# CTRL_MMR0_CFG0 register map
Vendor: Texas Instruments
Registers are 32-bit, read-write, reset 0x0 unless marked. A register's access mark holds for its fields unless they carry their own. Offsets are as the file gives them; [hi:lo] are bit positions; {n}, {i} and the like mark numbered series.

## CTRL_MMR0_CFG0 (part 3 of 10)
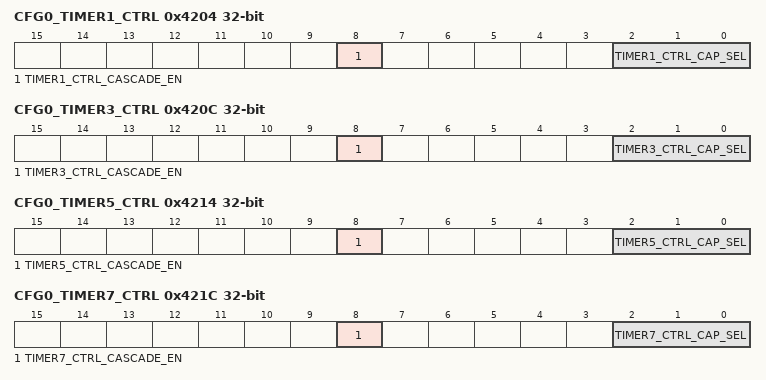
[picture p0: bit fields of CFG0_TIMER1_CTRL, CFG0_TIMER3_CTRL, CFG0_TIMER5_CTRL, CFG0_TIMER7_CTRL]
0x4204 CFG0_TIMER1_CTRL — Controls TIMER1 operation
  [8] TIMER1_CTRL_CASCADE_EN — Enables cascading of TIMER1 to TIMER0
  [2:0] TIMER1_CTRL_CAP_SEL — Selects the TIMERIO input pin for capture input signal. This control is only used when TIMER1 is configured for capture operation. Field values (Others are reserved): 3'b000 - Use TIMERIO0 pin 3'b001 - Use TIMERIO1 pin 3'b010 - Use TIMERIO2 pin 3'b011 - Use TIMERIO3 pin 3'b100 - Use TIMERIO4 pin 3'b101 - Use TIMERIO5 pin 3'b110 - Use TIMERIO6 pin 3'b111 - Use TIMERIO7 pin
0x4208 CFG0_TIMER2_CTRL — Controls TIMER2 operation
  [2:0] TIMER2_CTRL_CAP_SEL — Selects the TIMERIO input pin for capture input signal. This control is only used when TIMER2 is configured for capture operation. Field values (Others are reserved): 3'b000 - Use TIMERIO0 pin 3'b001 - Use TIMERIO1 pin 3'b010 - Use TIMERIO2 pin 3'b011 - Use TIMERIO3 pin 3'b100 - Use TIMERIO4 pin 3'b101 - Use TIMERIO5 pin 3'b110 - Use TIMERIO6 pin 3'b111 - Use TIMERIO7 pin
0x420C CFG0_TIMER3_CTRL — Controls TIMER3 operation
  [8] TIMER3_CTRL_CASCADE_EN — Enables cascading of TIMER3 to TIMER2
  [2:0] TIMER3_CTRL_CAP_SEL — Selects the TIMERIO input pin for capture input signal. This control is only used when TIMER3 is configured for capture operation. Field values (Others are reserved): 3'b000 - Use TIMERIO0 pin 3'b001 - Use TIMERIO1 pin 3'b010 - Use TIMERIO2 pin 3'b011 - Use TIMERIO3 pin 3'b100 - Use TIMERIO4 pin 3'b101 - Use TIMERIO5 pin 3'b110 - Use TIMERIO6 pin 3'b111 - Use TIMERIO7 pin
0x4210 CFG0_TIMER4_CTRL — Controls TIMER4 operation
  [2:0] TIMER4_CTRL_CAP_SEL — Selects the TIMERIO input pin for capture input signal. This control is only used when TIMER4 is configured for capture operation. Field values (Others are reserved): 3'b000 - Use TIMERIO0 pin 3'b001 - Use TIMERIO1 pin 3'b010 - Use TIMERIO2 pin 3'b011 - Use TIMERIO3 pin 3'b100 - Use TIMERIO4 pin 3'b101 - Use TIMERIO5 pin 3'b110 - Use TIMERIO6 pin 3'b111 - Use TIMERIO7 pin
0x4214 CFG0_TIMER5_CTRL — Controls TIMER5 operation
  [8] TIMER5_CTRL_CASCADE_EN — Enables cascading of TIMER5 to TIMER4
  [2:0] TIMER5_CTRL_CAP_SEL — Selects the TIMERIO input pin for capture input signal. This control is only used when TIMER5 is configured for capture operation. Field values (Others are reserved): 3'b000 - Use TIMERIO0 pin 3'b001 - Use TIMERIO1 pin 3'b010 - Use TIMERIO2 pin 3'b011 - Use TIMERIO3 pin 3'b100 - Use TIMERIO4 pin 3'b101 - Use TIMERIO5 pin 3'b110 - Use TIMERIO6 pin 3'b111 - Use TIMERIO7 pin
0x4218 CFG0_TIMER6_CTRL — Controls TIMER6 operation
  [2:0] TIMER6_CTRL_CAP_SEL — Selects the TIMERIO input pin for capture input signal. This control is only used when TIMER6 is configured for capture operation. Field values (Others are reserved): 3'b000 - Use TIMERIO0 pin 3'b001 - Use TIMERIO1 pin 3'b010 - Use TIMERIO2 pin 3'b011 - Use TIMERIO3 pin 3'b100 - Use TIMERIO4 pin 3'b101 - Use TIMERIO5 pin 3'b110 - Use TIMERIO6 pin 3'b111 - Use TIMERIO7 pin
0x421C CFG0_TIMER7_CTRL — Controls TIMER7 operation
  [8] TIMER7_CTRL_CASCADE_EN — Enables cascading of TIMER7 to TIMER6
  [2:0] TIMER7_CTRL_CAP_SEL — Selects the TIMERIO input pin for capture input signal. This control is only used when TIMER7 is configured for capture operation. Field values (Others are reserved): 3'b000 - Use TIMERIO0 pin 3'b001 - Use TIMERIO1 pin 3'b010 - Use TIMERIO2 pin 3'b011 - Use TIMERIO3 pin 3'b100 - Use TIMERIO4 pin 3'b101 - Use TIMERIO5 pin 3'b110 - Use TIMERIO6 pin 3'b111 - Use TIMERIO7 pin
0x4220 CFG0_TIMER8_CTRL — Controls TIMER8 operation
  [2:0] TIMER8_CTRL_CAP_SEL — Selects the TIMERIO input pin for capture input signal. This control is only used when TIMER8 is configured for capture operation. Field values (Others are reserved): 3'b000 - Use TIMERIO0 pin 3'b001 - Use TIMERIO1 pin 3'b010 - Use TIMERIO2 pin 3'b011 - Use TIMERIO3 pin 3'b100 - Use TIMERIO4 pin 3'b101 - Use TIMERIO5 pin 3'b110 - Use TIMERIO6 pin 3'b111 - Use TIMERIO7 pin
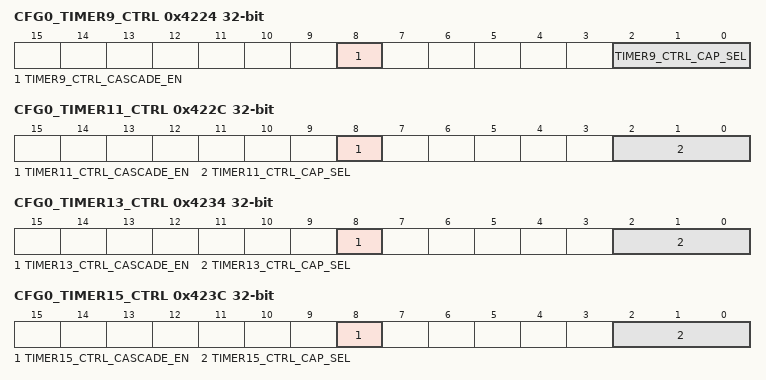
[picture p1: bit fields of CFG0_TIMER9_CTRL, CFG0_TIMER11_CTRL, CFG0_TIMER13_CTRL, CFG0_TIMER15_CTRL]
0x4224 CFG0_TIMER9_CTRL — Controls TIMER9 operation
  [8] TIMER9_CTRL_CASCADE_EN — Enables cascading of TIMER9 to TIMER8
  [2:0] TIMER9_CTRL_CAP_SEL — Selects the TIMERIO input pin for capture input signal. This control is only used when TIMER9 is configured for capture operation. Field values (Others are reserved): 3'b000 - Use TIMERIO0 pin 3'b001 - Use TIMERIO1 pin 3'b010 - Use TIMERIO2 pin 3'b011 - Use TIMERIO3 pin 3'b100 - Use TIMERIO4 pin 3'b101 - Use TIMERIO5 pin 3'b110 - Use TIMERIO6 pin 3'b111 - Use TIMERIO7 pin
0x4228 CFG0_TIMER10_CTRL — Controls TIMER10 operation
  [2:0] TIMER10_CTRL_CAP_SEL — Selects the TIMERIO input pin for capture input signal. This control is only used when TIMER10 is configured for capture operation. Field values (Others are reserved): 3'b000 - Use TIMERIO0 pin 3'b001 - Use TIMERIO1 pin 3'b010 - Use TIMERIO2 pin 3'b011 - Use TIMERIO3 pin 3'b100 - Use TIMERIO4 pin 3'b101 - Use TIMERIO5 pin 3'b110 - Use TIMERIO6 pin 3'b111 - Use TIMERIO7 pin
0x422C CFG0_TIMER11_CTRL — Controls TIMER11 operation
  [8] TIMER11_CTRL_CASCADE_EN — Enables cascading of TIMER11 to TIMER10
  [2:0] TIMER11_CTRL_CAP_SEL — Selects the TIMERIO input pin for capture input signal. This control is only used when TIMER11 is configured for capture operation. Field values (Others are reserved): 3'b000 - Use TIMERIO0 pin 3'b001 - Use TIMERIO1 pin 3'b010 - Use TIMERIO2 pin 3'b011 - Use TIMERIO3 pin 3'b100 - Use TIMERIO4 pin 3'b101 - Use TIMERIO5 pin 3'b110 - Use TIMERIO6 pin 3'b111 - Use TIMERIO7 pin
0x4230 CFG0_TIMER12_CTRL — Controls TIMER12 operation
  [2:0] TIMER12_CTRL_CAP_SEL — Selects the TIMERIO input pin for capture input signal. This control is only used when TIMER12 is configured for capture operation. Field values (Others are reserved): 3'b000 - Use TIMERIO0 pin 3'b001 - Use TIMERIO1 pin 3'b010 - Use TIMERIO2 pin 3'b011 - Use TIMERIO3 pin 3'b100 - Use TIMERIO4 pin 3'b101 - Use TIMERIO5 pin 3'b110 - Use TIMERIO6 pin 3'b111 - Use TIMERIO7 pin
0x4234 CFG0_TIMER13_CTRL — Controls TIMER13 operation
  [8] TIMER13_CTRL_CASCADE_EN — Enables cascading of TIMER13 to TIMER12
  [2:0] TIMER13_CTRL_CAP_SEL — Selects the TIMERIO input pin for capture input signal. This control is only used when TIMER13 is configured for capture operation. Field values (Others are reserved): 3'b000 - Use TIMERIO0 pin 3'b001 - Use TIMERIO1 pin 3'b010 - Use TIMERIO2 pin 3'b011 - Use TIMERIO3 pin 3'b100 - Use TIMERIO4 pin 3'b101 - Use TIMERIO5 pin 3'b110 - Use TIMERIO6 pin 3'b111 - Use TIMERIO7 pin
0x4238 CFG0_TIMER14_CTRL — Controls TIMER14 operation
  [2:0] TIMER14_CTRL_CAP_SEL — Selects the TIMERIO input pin for capture input signal. This control is only used when TIMER14 is configured for capture operation. Field values (Others are reserved): 3'b000 - Use TIMERIO0 pin 3'b001 - Use TIMERIO1 pin 3'b010 - Use TIMERIO2 pin 3'b011 - Use TIMERIO3 pin 3'b100 - Use TIMERIO4 pin 3'b101 - Use TIMERIO5 pin 3'b110 - Use TIMERIO6 pin 3'b111 - Use TIMERIO7 pin
0x423C CFG0_TIMER15_CTRL — Controls TIMER15 operation
  [8] TIMER15_CTRL_CASCADE_EN — Enables cascading of TIMER15 to TIMER14
  [2:0] TIMER15_CTRL_CAP_SEL — Selects the TIMERIO input pin for capture input signal. This control is only used when TIMER15 is configured for capture operation. Field values (Others are reserved): 3'b000 - Use TIMERIO0 pin 3'b001 - Use TIMERIO1 pin 3'b010 - Use TIMERIO2 pin 3'b011 - Use TIMERIO3 pin 3'b100 - Use TIMERIO4 pin 3'b101 - Use TIMERIO5 pin 3'b110 - Use TIMERIO6 pin 3'b111 - Use TIMERIO7 pin
0x4240 CFG0_TIMER16_CTRL — Controls TIMER16 operation
  [2:0] TIMER16_CTRL_CAP_SEL — Selects the TIMERIO input pin for capture input signal. This control is only used when TIMER16 is configured for capture operation. Field values (Others are reserved): 3'b000 - Use TIMERIO0 pin 3'b001 - Use TIMERIO1 pin 3'b010 - Use TIMERIO2 pin 3'b011 - Use TIMERIO3 pin 3'b100 - Use TIMERIO4 pin 3'b101 - Use TIMERIO5 pin 3'b110 - Use TIMERIO6 pin 3'b111 - Use TIMERIO7 pin
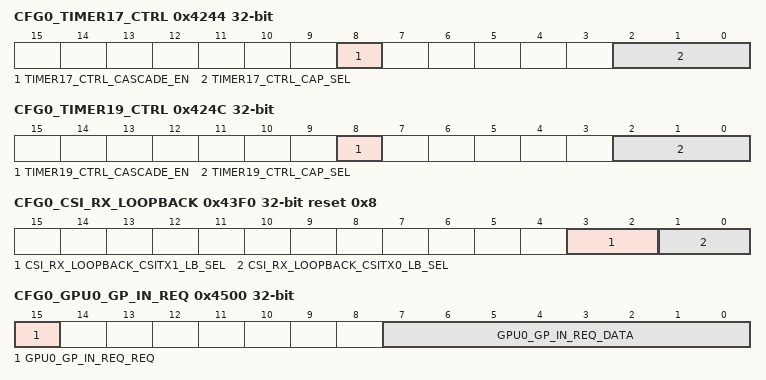
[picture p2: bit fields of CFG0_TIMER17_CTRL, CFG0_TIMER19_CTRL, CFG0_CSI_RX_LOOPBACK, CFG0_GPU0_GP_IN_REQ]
0x4244 CFG0_TIMER17_CTRL — Controls TIMER17 operation
  [8] TIMER17_CTRL_CASCADE_EN — Enables cascading of TIMER17 to TIMER16
  [2:0] TIMER17_CTRL_CAP_SEL — Selects the TIMERIO input pin for capture input signal. This control is only used when TIMER17 is configured for capture operation. Field values (Others are reserved): 3'b000 - Use TIMERIO0 pin 3'b001 - Use TIMERIO1 pin 3'b010 - Use TIMERIO2 pin 3'b011 - Use TIMERIO3 pin 3'b100 - Use TIMERIO4 pin 3'b101 - Use TIMERIO5 pin 3'b110 - Use TIMERIO6 pin 3'b111 - Use TIMERIO7 pin
0x4248 CFG0_TIMER18_CTRL — Controls TIMER18 operation
  [2:0] TIMER18_CTRL_CAP_SEL — Selects the TIMERIO input pin for capture input signal. This control is only used when TIMER18 is configured for capture operation. Field values (Others are reserved): 3'b000 - Use TIMERIO0 pin 3'b001 - Use TIMERIO1 pin 3'b010 - Use TIMERIO2 pin 3'b011 - Use TIMERIO3 pin 3'b100 - Use TIMERIO4 pin 3'b101 - Use TIMERIO5 pin 3'b110 - Use TIMERIO6 pin 3'b111 - Use TIMERIO7 pin
0x424C CFG0_TIMER19_CTRL — Controls TIMER19 operation
  [8] TIMER19_CTRL_CASCADE_EN — Enables cascading of TIMER19 to TIMER18
  [2:0] TIMER19_CTRL_CAP_SEL — Selects the TIMERIO input pin for capture input signal. This control is only used when TIMER19 is configured for capture operation. Field values (Others are reserved): 3'b000 - Use TIMERIO0 pin 3'b001 - Use TIMERIO1 pin 3'b010 - Use TIMERIO2 pin 3'b011 - Use TIMERIO3 pin 3'b100 - Use TIMERIO4 pin 3'b101 - Use TIMERIO5 pin 3'b110 - Use TIMERIO6 pin 3'b111 - Use TIMERIO7 pin
{0x4280+4i} CFG0_TIMERIO{i}_CTRL (i=0..7) — Controls Timer IO muxing
  [4:0] TIMERIO{i}_CTRL_OUT_SEL — Selects the source of the TIMERIO{i} output Field values (Others are reserved): 5'b00000 - TIMERIO{i} is driven by TIMER0 output 5'b00001 - TIMERIO{i} is driven by TIMER1 output 5'b00010 - TIMERIO{i} is driven by TIMER2 output 5'b00011 - TIMERIO{i} is driven by TIMER3 output 5'b00100 - TIMERIO{i} is driven by TIMER4 output 5'b00101 - TIMERIO{i} is driven by TIMER5 output 5'b00110 - TIMERIO{i} is driven by TIMER6 output 5'b00111 - TIMERIO{i} is driven by TIMER7 output 5'b01000 - TIMERIO{i} is driven by TIMER8 output 5'b01001 - TIMERIO{i} is driven by TIMER9 output 5'b01010 - TIMERIO{i} is driven by TIMER10 output 5'b01011 - TIMERIO{i} is driven by TIMER11 output 5'b01100 - TIMERIO{i} is driven by TIMER12 output 5'b01101 - TIMERIO{i} is driven by TIMER13 output 5'b01110 - TIMERIO{i} is driven by TIMER14 output 5'b01111 - TIMERIO{i} is driven by TIMER15 output 5'b10000 - TIMERIO{i} is driven by TIMER16 output 5'b10001 - TIMERIO{i} is driven by TIMER17 output 5'b10010 - TIMERIO{i} is driven by TIMER18 output 5'b10011 - TIMERIO{i} is driven by TIMER19 output
0x42E0 CFG0_I2C0_CTRL — Controls I2C0 operation for open drain I/Os
  [0] I2C0_CTRL_HS_MCS_EN — HS Mode master current source enable.When set, enables the current-source pull-up on the SCL output. Only one master on the I2C bus should enable SCL current sourcing.
0x4300 CFG0_DPHY_TX0_CTRL — Controls DPHY_TX0 operation
  [1:0] DPHY_TX0_CTRL_LANE_FUNC_SEL — Selects the source for the 4 lanes of DPHY_TX 0 Field values (Others are reserved): 2'b00 - IP1 (DSI_0 PPI0) 2'b01 - IP2 (CSI-TX0)
0x4304 CFG0_DPHY_TX1_CTRL — Controls DPHY_TX1 operation
  [1:0] DPHY_TX1_CTRL_LANE_FUNC_SEL — Selects the source for the 4 lanes of DPHY_TX 1 Field values (Others are reserved): 2'b00 - IP1 (DSI_1 PPI0) 2'b01 - IP2 (CSI-TX1)
0x4310 CFG0_EDP0_CTRL — Controls eDP0 operation
  [8] EDP0_CTRL_RESET_ISO — Reset isolationWhen set, enables reset isolation of eDP PHY
0x4320 CFG0_VPAC0_CAL0_CTRL — Controls VPAC0 Camera Adaptive Layer 0 interface operation
  [1:0] VPAC0_CAL0_CTRL_CAL_SEL — Selects the CSI_RX source for the VPAC CAL0 input Field values (Others are reserved): 2'b00 - CSI-RX 0 2'b01 - CSI-RX 1 2'b10 - CSI-RX 2 2'b11 - Reserved
0x4330 CFG0_VPAC1_CAL0_CTRL — Controls VPAC1 Camera Adaptive Layer 0 interface operation
  [1:0] VPAC1_CAL0_CTRL_CAL_SEL — Selects the CSI_RX source for the VPAC CAL0 input Field values (Others are reserved): 2'b00 - CSI-RX 0 2'b01 - CSI-RX 1 2'b10 - CSI-RX 2 2'b11 - Reserved
0x43F0 CFG0_CSI_RX_LOOPBACK reset 0x8 — Controls loopback of CSI-RX inputs to CSI-TX inputs for diagnostics.
  [3:2] CSI_RX_LOOPBACK_CSITX1_LB_SEL — Selects the CSI-RX loopback source for CSI-TX1 Field values (Others are reserved): 2'b00 - CSI-RX 0 2'b01 - CSI-RX 1 2'b10 - CSI-RX 2 2'b11 - Reserved
  [1:0] CSI_RX_LOOPBACK_CSITX0_LB_SEL — Selects the CSI-RX loopback source for CSI-TX0. Field values (Others are reserved): 2'b00 - CSI-RX 0 2'b01 - CSI-RX 1 2'b10 - CSI-RX 2 2'b11 - Reserved
0x4500 CFG0_GPU0_GP_IN_REQ — Generates GPIO input event to GPU0
  [15] GPU0_GP_IN_REQ_REQ — Input request. This bit is set to generate a GPIO request to the GPU to read the requestor data input. This bit should be cleared by the requestor after the GPU has acknowledged the request.
  [7:0] GPU0_GP_IN_REQ_DATA — GPIO requestor data input to the GPU
0x4504 CFG0_GPU0_GP_IN_ACK ro — Acknowledge for GPIO input event from GPU0
  [15] GPU0_GP_IN_ACK_ACK — Input acknowledge. The GPU will set this bit to acknowledge a GPIO input request. This will generate a gpu_gpio_ack interrupt which will be cleared when the requestor clears the req bit in the GPU_GP_IN_REQ register.
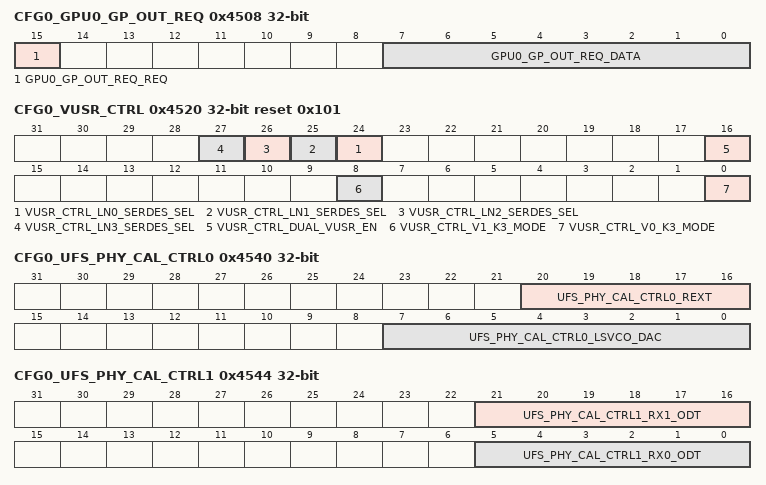
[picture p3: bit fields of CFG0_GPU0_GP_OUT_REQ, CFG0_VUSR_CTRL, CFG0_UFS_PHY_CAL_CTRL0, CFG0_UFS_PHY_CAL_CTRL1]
0x4508 CFG0_GPU0_GP_OUT_REQ ro — Generates GPIO output event from GPU0
  [15] GPU0_GP_OUT_REQ_REQ — Output request. This bit is set to generate a GPIO request from the GPU to read the requestor data output. This will generate a gpu_gpio_req interrupt which will be cleared when the receiver clears the ack bit in the GPU_GPIO_OUT_ACK register. This bit will be cleared by the GPU after the request has been acknowledged.
  [7:0] GPU0_GP_OUT_REQ_DATA — GPIO requestor data output from the GPU
0x450C CFG0_GPU0_GP_OUT_ACK — Acknowledge for GPIO output event to GPU0
  [15] GPU0_GP_OUT_ACK_ACK — Output acknowledge. The receiver of the gpu_gpio_req interrupt will set this bit to acknowledge the GPIO output request. This bit is cleared when the GPU deasserts its gpio_output_req signal.
0x4520 CFG0_VUSR_CTRL reset 0x101 — Controls operation of the dual VUSR (Hyperlink) module
  [n+24] VUSR_CTRL_LN{n}_SERDES_SEL (n=0..3) — Serdes Selection - Lane {n}The Hyperlink lane{n} interface can be mapped to 2 different SERDES lanes. This bit selects which SERDES drives the VUSR lane{n} PIPE interface input clock, data and control signals. Programming should align with the SERDES0_LN{n}_CTRL and SERDES4_LN{n}_CTRL lane_func_sel programming. 0 - SERDES0 Ln{n} drives VUSR lane{n} inputs 1 - SERDES4 Ln{n} drives VUSR lane{n} inputs
  [16] VUSR_CTRL_DUAL_VUSR_EN — Selects single or dual VUSR interface operation 0 - Single VUSR interface (VUSR0) enabled 1 - Dual VUSR interface (VUSR0 & VUSR1) enabled
  [8] VUSR_CTRL_V1_K3_MODE — VUSR1 interface operational mode 0 - Legacy (KS2) addressing/interface mode 1 - Enhanced (KS3) addressing/interface mode
  [0] VUSR_CTRL_V0_K3_MODE — VUSR0 interface operational mode 0 - Legacy (KS2) addressing/interface mode 1 - Enhanced (KS3) addressing/interface mode
0x4540 CFG0_UFS_PHY_CAL_CTRL0 — Controls UFS LSVCO calibration
  [20:16] UFS_PHY_CAL_CTRL0_REXT — REXT calibration trim value
  [7:0] UFS_PHY_CAL_CTRL0_LSVCO_DAC — LS VCO calibration trim value
0x4544 CFG0_UFS_PHY_CAL_CTRL1 — Controls UFS RX calibration
  [21:16] UFS_PHY_CAL_CTRL1_RX1_ODT — RX1 DP/DN 100-ohm differential impedance trim value
  [5:0] UFS_PHY_CAL_CTRL1_RX0_ODT — RX0 DP/DN 100-ohm differential impedance trim value
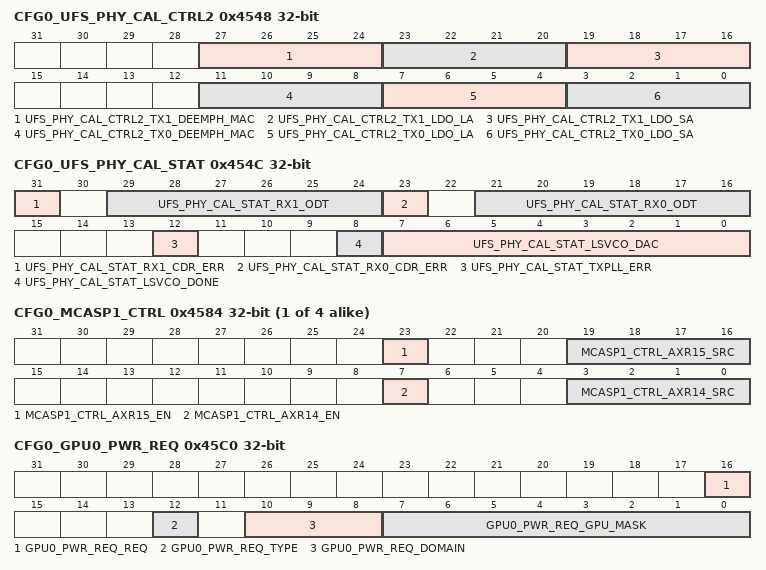
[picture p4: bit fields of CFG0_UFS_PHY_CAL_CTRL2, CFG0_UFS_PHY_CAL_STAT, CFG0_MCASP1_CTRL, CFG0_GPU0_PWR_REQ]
0x4548 CFG0_UFS_PHY_CAL_CTRL2 — Controls UFS TX calibration
  [27:24] UFS_PHY_CAL_CTRL2_TX1_DEEMPH_MAC — TX1 DP/DN de-emphasis trim value
  [23:20] UFS_PHY_CAL_CTRL2_TX1_LDO_LA — TX1 DP/DN large amplitude trim value
  [19:16] UFS_PHY_CAL_CTRL2_TX1_LDO_SA — TX1 DP/DN small amplitude trim value
  [11:8] UFS_PHY_CAL_CTRL2_TX0_DEEMPH_MAC — TX0 DP/DN de-emphasis trim value
  [7:4] UFS_PHY_CAL_CTRL2_TX0_LDO_LA — TX0 DP/DN large amplitude trim value
  [3:0] UFS_PHY_CAL_CTRL2_TX0_LDO_SA — TX0 DP/DN small amplitude trim value
0x454C CFG0_UFS_PHY_CAL_STAT ro — Shows UFS calibration procedure results
  [31] UFS_PHY_CAL_STAT_RX1_CDR_ERR — RX1 CDR calibration timeout error
  [29:24] UFS_PHY_CAL_STAT_RX1_ODT — RX1 DP/DN ODT calibration result
  [23] UFS_PHY_CAL_STAT_RX0_CDR_ERR — RX0 CDR calibration timeout error
  [21:16] UFS_PHY_CAL_STAT_RX0_ODT — RX0 DP/DN ODT calibration result
  [12] UFS_PHY_CAL_STAT_TXPLL_ERR — TX calibration timeout error
  [8] UFS_PHY_CAL_STAT_LSVCO_DONE — LS VCO calibration trim done
  [7:0] UFS_PHY_CAL_STAT_LSVCO_DAC — LS VCO calibration trim result
{0x4580+4i} CFG0_MCASP{i}_CTRL (i=1..4) — Controls McASP{i} operation
  [23] MCASP{i}_CTRL_AXR15_EN — Enable AXR15 receive data. 0 - AXR15 input driven 1'b0 1 - AXR15 input driven by AFSR/X input selected by axr15_src value
  [19:16] MCASP{i}_CTRL_AXR15_SRC — Selects one of the AFSX or AFSR inputs as the AXR15 data input Field values (Others are reserved): 4'b0000 - McASP0_AFSR 4'b0001 - McASP0_AFSX 4'b0010 - McASP1_AFSR 4'b0011 - McASP1_AFSX 4'b0100 - McASP2_AFSR 4'b0101 - McASP2_AFSX 4'b0110 - McASP3_AFSR 4'b0111 - McASP3_AFSX 4'b1000 - McASP4_AFSR 4'b1001 - McASP4_AFSX 4'b1010 - 0 4'b1011 - 0 4'b1100 - 0 4'b1101 - 0 4'b1110 - 0 4'b1111 - 0
  [7] MCASP{i}_CTRL_AXR14_EN — Enable AXR14 receive data. 0 - AXR14 input driven 1'b0 1 - AXR14 input driven by AFSR/X input selected by axr14_src value
  [3:0] MCASP{i}_CTRL_AXR14_SRC — Selects one of the AFSX or AFSR inputs as the AXR14 data input Field values (Others are reserved): 4'b0000 - McASP0_AFSR 4'b0001 - McASP0_AFSX 4'b0010 - McASP1_AFSR 4'b0011 - McASP1_AFSX 4'b0100 - McASP2_AFSR 4'b0101 - McASP2_AFSX 4'b0110 - McASP3_AFSR 4'b0111 - McASP3_AFSX 4'b1000 - McASP4_AFSR 4'b1001 - McASP4_AFSX 4'b1010 - 0 4'b1011 - 0 4'b1100 - 0 4'b1101 - 0 4'b1110 - 0 4'b1111 - 0
0x45C0 CFG0_GPU0_PWR_REQ ro — Indicates GPU0 power control interface requests
  [16] GPU0_PWR_REQ_REQ — Power control request. This bit is set by the GPU to request a Power Management event to the PM processor. This will generate a gpu0_pwr_req interrupt. The interrupt is cleared only when the GPU clears its pwrctrl_gpu_req output.
  [12] GPU0_PWR_REQ_TYPE — GPU request type. 0 - Power Down request 1 - Power Up request
  [10:8] GPU0_PWR_REQ_DOMAIN — GPU request mask. Indicates GPU domain to which the power event applies. For mapping refer to GPU RGX_CR_POWER_EVENT register.
  [7:0] GPU0_PWR_REQ_GPU_MASK — GPU request mask. One bit per GPU indicating to which GPUs the power event applies. Mask bits are indexed by GPU_ID
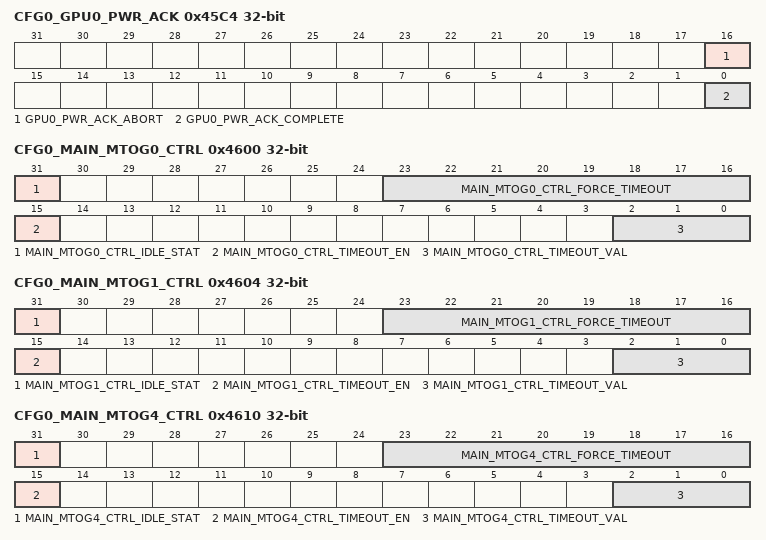
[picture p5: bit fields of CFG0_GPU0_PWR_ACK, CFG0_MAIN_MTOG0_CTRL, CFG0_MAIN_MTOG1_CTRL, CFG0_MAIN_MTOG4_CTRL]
0x45C4 CFG0_GPU0_PWR_ACK — Controls GPU0 power control interface request acknowledgement
  [16] GPU0_PWR_ACK_ABORT — Power control abort. This bit is set by the PM processor to that the GPU power control request could not be completed. The bit is cleared to 0 when gpu0_pwr_req goes low.
  [0] GPU0_PWR_ACK_COMPLETE — Power control complete. This bit is set by the PM processor to indicate sucessful completion of the GPU power control request. The bit is cleared to 0 when gpu0_pwr_req goes low.
0x4600 CFG0_MAIN_MTOG0_CTRL access per field — Controls timeout operation of read transactions from the GIC master port
  [31] MAIN_MTOG0_CTRL_IDLE_STAT ro — Idle statusWhen high, indicates MTOG0 is idle.
  [23:16] MAIN_MTOG0_CTRL_FORCE_TIMEOUT rw — Force TimeoutForces a flush of the interface transactions. This bitfield is only relevant if timeout_en=1. After forcing a timeout by writing the encoded value, the force_timeout and timeout_en bitfields must be cleared to clear the timeout before re-enabling the gasket. 8'h95 - Force a gasket timeoutAll others - Normal operation
  [15] MAIN_MTOG0_CTRL_TIMEOUT_EN rw — Timeout Enable 1'b0 - Disable the gasket. Clear the interrupt and reset the counter 1'b1 - Enable the timeout gasket functions
  [2:0] MAIN_MTOG0_CTRL_TIMEOUT_VAL rw — Gasket Timeout ValueSelects the number of clock cycles before the interface is considered to have timed out Field values (Others are reserved): 3'b000 - 1024 clock cycles 3'b001 - 4096 clock cycles 3'b010 - 16,384 clock cycles 3'b011 - 65,536 clock cycles 3'b100 - 262,144 clock cycles 3'b101 - 1,048,576 clock cycles 3'b110 - 2,097,152 clock cycles 3'b111 - 4,194,303 clock cycles
0x4604 CFG0_MAIN_MTOG1_CTRL access per field — Controls timeout operation of write transactions from the GIC master port
  [31] MAIN_MTOG1_CTRL_IDLE_STAT ro — Idle statusWhen high, indicates MTOG1 is idle.
  [23:16] MAIN_MTOG1_CTRL_FORCE_TIMEOUT rw — Force TimeoutForces a flush of the interface transactions. This bitfield is only relevant if timeout_en=1. After forcing a timeout by writing the encoded value, the force_timeout and timeout_en bitfields must be cleared to clear the timeout before re-enabling the gasket. 8'h95 - Force a gasket timeoutAll others - Normal operation
  [15] MAIN_MTOG1_CTRL_TIMEOUT_EN rw — Timeout Enable 1'b0 - Disable the gasket. Clear the interrupt and reset the counter 1'b1 - Enable the timeout gasket functions
  [2:0] MAIN_MTOG1_CTRL_TIMEOUT_VAL rw — Gasket Timeout ValueSelects the number of clock cycles before the interface is considered to have timed out Field values (Others are reserved): 3'b000 - 1024 clock cycles 3'b001 - 4096 clock cycles 3'b010 - 16,384 clock cycles 3'b011 - 65,536 clock cycles 3'b100 - 262,144 clock cycles 3'b101 - 1,048,576 clock cycles 3'b110 - 2,097,152 clock cycles 3'b111 - 4,194,303 clock cycles
0x4610 CFG0_MAIN_MTOG4_CTRL access per field — Controls timeout operation of read transactions from the eMMC1 master port
  [31] MAIN_MTOG4_CTRL_IDLE_STAT ro — Idle statusWhen high, indicates MTOG4 is idle.
  [23:16] MAIN_MTOG4_CTRL_FORCE_TIMEOUT rw — Force TimeoutForces a flush of the interface transactions. This bitfield is only relevant if timeout_en=1. After forcing a timeout by writing the encoded value, the force_timeout and timeout_en bitfields must be cleared to clear the timeout before re-enabling the gasket. 8'h95 - Force a gasket timeoutAll others - Normal operation
  [15] MAIN_MTOG4_CTRL_TIMEOUT_EN rw — Timeout Enable 1'b0 - Disable the gasket. Clear the interrupt and reset the counter 1'b1 - Enable the timeout gasket functions
  [2:0] MAIN_MTOG4_CTRL_TIMEOUT_VAL rw — Gasket Timeout ValueSelects the number of clock cycles before the interface is considered to have timed out Field values (Others are reserved): 3'b000 - 1024 clock cycles 3'b001 - 4096 clock cycles 3'b010 - 16,384 clock cycles 3'b011 - 65,536 clock cycles 3'b100 - 262,144 clock cycles 3'b101 - 1,048,576 clock cycles 3'b110 - 2,097,152 clock cycles 3'b111 - 4,194,303 clock cycles
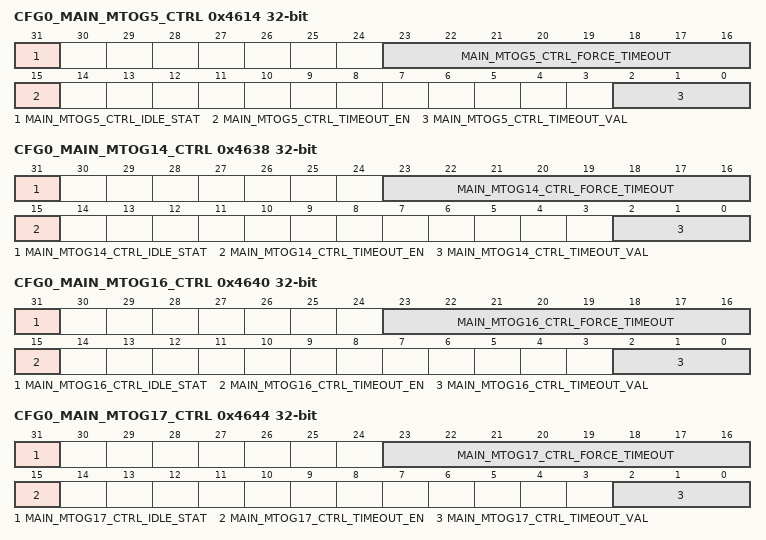
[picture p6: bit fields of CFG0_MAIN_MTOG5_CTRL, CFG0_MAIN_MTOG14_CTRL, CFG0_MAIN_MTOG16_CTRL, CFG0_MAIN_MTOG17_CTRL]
0x4614 CFG0_MAIN_MTOG5_CTRL access per field — Controls timeout operation of write transactions from the eMMC1 master port
  [31] MAIN_MTOG5_CTRL_IDLE_STAT ro — Idle statusWhen high, indicates MTOG5 is idle.
  [23:16] MAIN_MTOG5_CTRL_FORCE_TIMEOUT rw — Force TimeoutForces a flush of the interface transactions. This bitfield is only relevant if timeout_en=1. After forcing a timeout by writing the encoded value, the force_timeout and timeout_en bitfields must be cleared to clear the timeout before re-enabling the gasket. 8'h95 - Force a gasket timeoutAll others - Normal operation
  [15] MAIN_MTOG5_CTRL_TIMEOUT_EN rw — Timeout Enable 1'b0 - Disable the gasket. Clear the interrupt and reset the counter 1'b1 - Enable the timeout gasket functions
  [2:0] MAIN_MTOG5_CTRL_TIMEOUT_VAL rw — Gasket Timeout ValueSelects the number of clock cycles before the interface is considered to have timed out Field values (Others are reserved): 3'b000 - 1024 clock cycles 3'b001 - 4096 clock cycles 3'b010 - 16,384 clock cycles 3'b011 - 65,536 clock cycles 3'b100 - 262,144 clock cycles 3'b101 - 1,048,576 clock cycles 3'b110 - 2,097,152 clock cycles 3'b111 - 4,194,303 clock cycles
0x4638 CFG0_MAIN_MTOG14_CTRL access per field — Controls timeout operation of transactions from the NavSS PVU to VIRTSS
  [31] MAIN_MTOG14_CTRL_IDLE_STAT ro — Idle statusWhen high, indicates MTOG14 is idle.
  [23:16] MAIN_MTOG14_CTRL_FORCE_TIMEOUT rw — Force TimeoutForces a flush of the interface transactions. This bitfield is only relevant if timeout_en=1. After forcing a timeout by writing the encoded value, the force_timeout and timeout_en bitfields must be cleared to clear the timeout before re-enabling the gasket. 8'h95 - Force a gasket timeoutAll others - Normal operation
  [15] MAIN_MTOG14_CTRL_TIMEOUT_EN rw — Timeout Enable 1'b0 - Disable the gasket. Clear the interrupt and reset the counter 1'b1 - Enable the timeout gasket functions
  [2:0] MAIN_MTOG14_CTRL_TIMEOUT_VAL rw — Gasket Timeout ValueSelects the number of clock cycles before the interface is considered to have timed out Field values (Others are reserved): 3'b000 - 1024 clock cycles 3'b001 - 4096 clock cycles 3'b010 - 16,384 clock cycles 3'b011 - 65,536 clock cycles 3'b100 - 262,144 clock cycles 3'b101 - 1,048,576 clock cycles 3'b110 - 2,097,152 clock cycles 3'b111 - 4,194,303 clock cycles
0x4640 CFG0_MAIN_MTOG16_CTRL access per field — Controls timeout operation of read transactions from the MAIN R5 Clstr0 Core0 VBUSM Memory master port
  [31] MAIN_MTOG16_CTRL_IDLE_STAT ro — Idle statusWhen high, indicates MTOG16 is idle.
  [23:16] MAIN_MTOG16_CTRL_FORCE_TIMEOUT rw — Force TimeoutForces a flush of the interface transactions. This bitfield is only relevant if timeout_en=1. After forcing a timeout by writing the encoded value, the force_timeout and timeout_en bitfields must be cleared to clear the timeout before re-enabling the gasket. 8'h95 - Force a gasket timeoutAll others - Normal operation
  [15] MAIN_MTOG16_CTRL_TIMEOUT_EN rw — Timeout Enable 1'b0 - Disable the gasket. Clear the interrupt and reset the counter 1'b1 - Enable the timeout gasket functions
  [2:0] MAIN_MTOG16_CTRL_TIMEOUT_VAL rw — Gasket Timeout ValueSelects the number of clock cycles before the interface is considered to have timed out Field values (Others are reserved): 3'b000 - 1024 clock cycles 3'b001 - 4096 clock cycles 3'b010 - 16,384 clock cycles 3'b011 - 65,536 clock cycles 3'b100 - 262,144 clock cycles 3'b101 - 1,048,576 clock cycles 3'b110 - 2,097,152 clock cycles 3'b111 - 4,194,303 clock cycles
0x4644 CFG0_MAIN_MTOG17_CTRL access per field — Controls timeout operation of write transactions from the MAIN R5 Clstr0 Core0 VBUSM Memory master port
  [31] MAIN_MTOG17_CTRL_IDLE_STAT ro — Idle statusWhen high, indicates MTOG17 is idle.
  [23:16] MAIN_MTOG17_CTRL_FORCE_TIMEOUT rw — Force TimeoutForces a flush of the interface transactions. This bitfield is only relevant if timeout_en=1. After forcing a timeout by writing the encoded value, the force_timeout and timeout_en bitfields must be cleared to clear the timeout before re-enabling the gasket. 8'h95 - Force a gasket timeoutAll others - Normal operation
  [15] MAIN_MTOG17_CTRL_TIMEOUT_EN rw — Timeout Enable 1'b0 - Disable the gasket. Clear the interrupt and reset the counter 1'b1 - Enable the timeout gasket functions
  [2:0] MAIN_MTOG17_CTRL_TIMEOUT_VAL rw — Gasket Timeout ValueSelects the number of clock cycles before the interface is considered to have timed out Field values (Others are reserved): 3'b000 - 1024 clock cycles 3'b001 - 4096 clock cycles 3'b010 - 16,384 clock cycles 3'b011 - 65,536 clock cycles 3'b100 - 262,144 clock cycles 3'b101 - 1,048,576 clock cycles 3'b110 - 2,097,152 clock cycles 3'b111 - 4,194,303 clock cycles
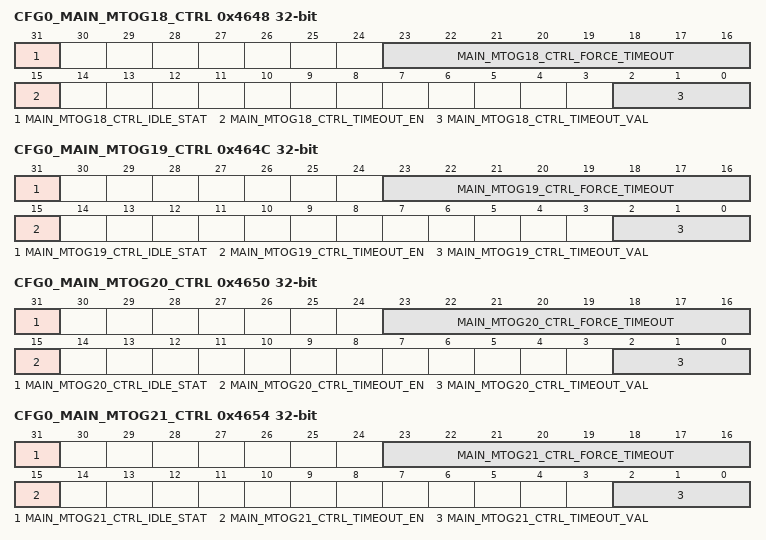
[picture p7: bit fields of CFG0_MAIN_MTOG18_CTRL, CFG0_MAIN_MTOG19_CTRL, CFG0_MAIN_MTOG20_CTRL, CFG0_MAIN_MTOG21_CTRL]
0x4648 CFG0_MAIN_MTOG18_CTRL access per field — Controls timeout operation of read transactions from the MAIN R5 Clstr0 Core1 VBUSM Memory master port
  [31] MAIN_MTOG18_CTRL_IDLE_STAT ro — Idle statusWhen high, indicates MTOG18 is idle.
  [23:16] MAIN_MTOG18_CTRL_FORCE_TIMEOUT rw — Force TimeoutForces a flush of the interface transactions. This bitfield is only relevant if timeout_en=1. After forcing a timeout by writing the encoded value, the force_timeout and timeout_en bitfields must be cleared to clear the timeout before re-enabling the gasket. 8'h95 - Force a gasket timeoutAll others - Normal operation
  [15] MAIN_MTOG18_CTRL_TIMEOUT_EN rw — Timeout Enable 1'b0 - Disable the gasket. Clear the interrupt and reset the counter 1'b1 - Enable the timeout gasket functions
  [2:0] MAIN_MTOG18_CTRL_TIMEOUT_VAL rw — Gasket Timeout ValueSelects the number of clock cycles before the interface is considered to have timed out Field values (Others are reserved): 3'b000 - 1024 clock cycles 3'b001 - 4096 clock cycles 3'b010 - 16,384 clock cycles 3'b011 - 65,536 clock cycles 3'b100 - 262,144 clock cycles 3'b101 - 1,048,576 clock cycles 3'b110 - 2,097,152 clock cycles 3'b111 - 4,194,303 clock cycles
0x464C CFG0_MAIN_MTOG19_CTRL access per field — Controls timeout operation of write transactions from the MAIN R5 Clstr0 Core1 VBUSM Memory master port
  [31] MAIN_MTOG19_CTRL_IDLE_STAT ro — Idle statusWhen high, indicates MTOG19 is idle.
  [23:16] MAIN_MTOG19_CTRL_FORCE_TIMEOUT rw — Force TimeoutForces a flush of the interface transactions. This bitfield is only relevant if timeout_en=1. After forcing a timeout by writing the encoded value, the force_timeout and timeout_en bitfields must be cleared to clear the timeout before re-enabling the gasket. 8'h95 - Force a gasket timeoutAll others - Normal operation
  [15] MAIN_MTOG19_CTRL_TIMEOUT_EN rw — Timeout Enable 1'b0 - Disable the gasket. Clear the interrupt and reset the counter 1'b1 - Enable the timeout gasket functions
  [2:0] MAIN_MTOG19_CTRL_TIMEOUT_VAL rw — Gasket Timeout ValueSelects the number of clock cycles before the interface is considered to have timed out Field values (Others are reserved): 3'b000 - 1024 clock cycles 3'b001 - 4096 clock cycles 3'b010 - 16,384 clock cycles 3'b011 - 65,536 clock cycles 3'b100 - 262,144 clock cycles 3'b101 - 1,048,576 clock cycles 3'b110 - 2,097,152 clock cycles 3'b111 - 4,194,303 clock cycles
0x4650 CFG0_MAIN_MTOG20_CTRL access per field — Controls timeout operation of read transactions from the MAIN R5 Clstr1 Core0 VBUSM Memory master port
  [31] MAIN_MTOG20_CTRL_IDLE_STAT ro — Idle statusWhen high, indicates MTOG20 is idle.
  [23:16] MAIN_MTOG20_CTRL_FORCE_TIMEOUT rw — Force TimeoutForces a flush of the interface transactions. This bitfield is only relevant if timeout_en=1. After forcing a timeout by writing the encoded value, the force_timeout and timeout_en bitfields must be cleared to clear the timeout before re-enabling the gasket. 8'h95 - Force a gasket timeoutAll others - Normal operation
  [15] MAIN_MTOG20_CTRL_TIMEOUT_EN rw — Timeout Enable 1'b0 - Disable the gasket. Clear the interrupt and reset the counter 1'b1 - Enable the timeout gasket functions
  [2:0] MAIN_MTOG20_CTRL_TIMEOUT_VAL rw — Gasket Timeout ValueSelects the number of clock cycles before the interface is considered to have timed out Field values (Others are reserved): 3'b000 - 1024 clock cycles 3'b001 - 4096 clock cycles 3'b010 - 16,384 clock cycles 3'b011 - 65,536 clock cycles 3'b100 - 262,144 clock cycles 3'b101 - 1,048,576 clock cycles 3'b110 - 2,097,152 clock cycles 3'b111 - 4,194,303 clock cycles
0x4654 CFG0_MAIN_MTOG21_CTRL access per field — Controls timeout operation of write transactions from the MAIN R5 Clstr1 Core0 VBUSM Memory master port
  [31] MAIN_MTOG21_CTRL_IDLE_STAT ro — Idle statusWhen high, indicates MTOG21 is idle.
  [23:16] MAIN_MTOG21_CTRL_FORCE_TIMEOUT rw — Force TimeoutForces a flush of the interface transactions. This bitfield is only relevant if timeout_en=1. After forcing a timeout by writing the encoded value, the force_timeout and timeout_en bitfields must be cleared to clear the timeout before re-enabling the gasket. 8'h95 - Force a gasket timeoutAll others - Normal operation
  [15] MAIN_MTOG21_CTRL_TIMEOUT_EN rw — Timeout Enable 1'b0 - Disable the gasket. Clear the interrupt and reset the counter 1'b1 - Enable the timeout gasket functions
  [2:0] MAIN_MTOG21_CTRL_TIMEOUT_VAL rw — Gasket Timeout ValueSelects the number of clock cycles before the interface is considered to have timed out Field values (Others are reserved): 3'b000 - 1024 clock cycles 3'b001 - 4096 clock cycles 3'b010 - 16,384 clock cycles 3'b011 - 65,536 clock cycles 3'b100 - 262,144 clock cycles 3'b101 - 1,048,576 clock cycles 3'b110 - 2,097,152 clock cycles 3'b111 - 4,194,303 clock cycles
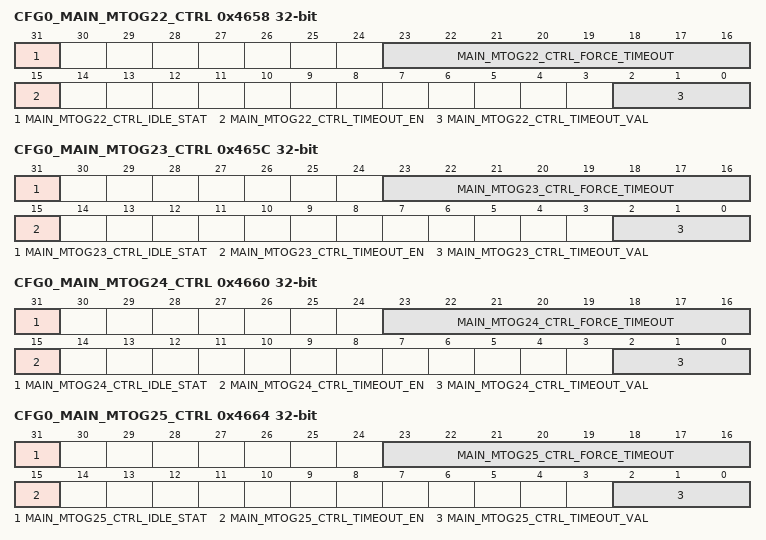
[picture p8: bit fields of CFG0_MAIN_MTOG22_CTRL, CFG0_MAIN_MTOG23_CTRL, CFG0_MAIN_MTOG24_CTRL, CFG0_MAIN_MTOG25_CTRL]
0x4658 CFG0_MAIN_MTOG22_CTRL access per field — Controls timeout operation of read transactions from the MAIN R5 Clstr1 Core1 VBUSM Memory master port
  [31] MAIN_MTOG22_CTRL_IDLE_STAT ro — Idle statusWhen high, indicates MTOG22 is idle.
  [23:16] MAIN_MTOG22_CTRL_FORCE_TIMEOUT rw — Force TimeoutForces a flush of the interface transactions. This bitfield is only relevant if timeout_en=1. After forcing a timeout by writing the encoded value, the force_timeout and timeout_en bitfields must be cleared to clear the timeout before re-enabling the gasket. 8'h95 - Force a gasket timeoutAll others - Normal operation
  [15] MAIN_MTOG22_CTRL_TIMEOUT_EN rw — Timeout Enable 1'b0 - Disable the gasket. Clear the interrupt and reset the counter 1'b1 - Enable the timeout gasket functions
  [2:0] MAIN_MTOG22_CTRL_TIMEOUT_VAL rw — Gasket Timeout ValueSelects the number of clock cycles before the interface is considered to have timed out Field values (Others are reserved): 3'b000 - 1024 clock cycles 3'b001 - 4096 clock cycles 3'b010 - 16,384 clock cycles 3'b011 - 65,536 clock cycles 3'b100 - 262,144 clock cycles 3'b101 - 1,048,576 clock cycles 3'b110 - 2,097,152 clock cycles 3'b111 - 4,194,303 clock cycles
0x465C CFG0_MAIN_MTOG23_CTRL access per field — Controls timeout operation of write transactions from the MAIN R5 Clstr1 Core 1 VBUSM Memory master port
  [31] MAIN_MTOG23_CTRL_IDLE_STAT ro — Idle statusWhen high, indicates MTOG23 is idle.
  [23:16] MAIN_MTOG23_CTRL_FORCE_TIMEOUT rw — Force TimeoutForces a flush of the interface transactions. This bitfield is only relevant if timeout_en=1. After forcing a timeout by writing the encoded value, the force_timeout and timeout_en bitfields must be cleared to clear the timeout before re-enabling the gasket. 8'h95 - Force a gasket timeoutAll others - Normal operation
  [15] MAIN_MTOG23_CTRL_TIMEOUT_EN rw — Timeout Enable 1'b0 - Disable the gasket. Clear the interrupt and reset the counter 1'b1 - Enable the timeout gasket functions
  [2:0] MAIN_MTOG23_CTRL_TIMEOUT_VAL rw — Gasket Timeout ValueSelects the number of clock cycles before the interface is considered to have timed out Field values (Others are reserved): 3'b000 - 1024 clock cycles 3'b001 - 4096 clock cycles 3'b010 - 16,384 clock cycles 3'b011 - 65,536 clock cycles 3'b100 - 262,144 clock cycles 3'b101 - 1,048,576 clock cycles 3'b110 - 2,097,152 clock cycles 3'b111 - 4,194,303 clock cycles
0x4660 CFG0_MAIN_MTOG24_CTRL access per field — Controls timeout operation of real time transactions from High Speed IO masters
  [31] MAIN_MTOG24_CTRL_IDLE_STAT ro — Idle statusWhen high, indicates MTOG24 is idle.
  [23:16] MAIN_MTOG24_CTRL_FORCE_TIMEOUT rw — Force TimeoutForces a flush of the interface transactions. This bitfield is only relevant if timeout_en=1. After forcing a timeout by writing the encoded value, the force_timeout and timeout_en bitfields must be cleared to clear the timeout before re-enabling the gasket. 8'h95 - Force a gasket timeoutAll others - Normal operation
  [15] MAIN_MTOG24_CTRL_TIMEOUT_EN rw — Timeout Enable 1'b0 - Disable the gasket. Clear the interrupt and reset the counter 1'b1 - Enable the timeout gasket functions
  [2:0] MAIN_MTOG24_CTRL_TIMEOUT_VAL rw — Gasket Timeout ValueSelects the number of clock cycles before the interface is considered to have timed out Field values (Others are reserved): 3'b000 - 1024 clock cycles 3'b001 - 4096 clock cycles 3'b010 - 16,384 clock cycles 3'b011 - 65,536 clock cycles 3'b100 - 262,144 clock cycles 3'b101 - 1,048,576 clock cycles 3'b110 - 2,097,152 clock cycles 3'b111 - 4,194,303 clock cycles
0x4664 CFG0_MAIN_MTOG25_CTRL access per field — Controls timeout operation of non-real time transactions from High Speed IO masters
  [31] MAIN_MTOG25_CTRL_IDLE_STAT ro — Idle statusWhen high, indicates MTOG25 is idle.
  [23:16] MAIN_MTOG25_CTRL_FORCE_TIMEOUT rw — Force TimeoutForces a flush of the interface transactions. This bitfield is only relevant if timeout_en=1. After forcing a timeout by writing the encoded value, the force_timeout and timeout_en bitfields must be cleared to clear the timeout before re-enabling the gasket. 8'h95 - Force a gasket timeoutAll others - Normal operation
  [15] MAIN_MTOG25_CTRL_TIMEOUT_EN rw — Timeout Enable 1'b0 - Disable the gasket. Clear the interrupt and reset the counter 1'b1 - Enable the timeout gasket functions
  [2:0] MAIN_MTOG25_CTRL_TIMEOUT_VAL rw — Gasket Timeout ValueSelects the number of clock cycles before the interface is considered to have timed out Field values (Others are reserved): 3'b000 - 1024 clock cycles 3'b001 - 4096 clock cycles 3'b010 - 16,384 clock cycles 3'b011 - 65,536 clock cycles 3'b100 - 262,144 clock cycles 3'b101 - 1,048,576 clock cycles 3'b110 - 2,097,152 clock cycles 3'b111 - 4,194,303 clock cycles
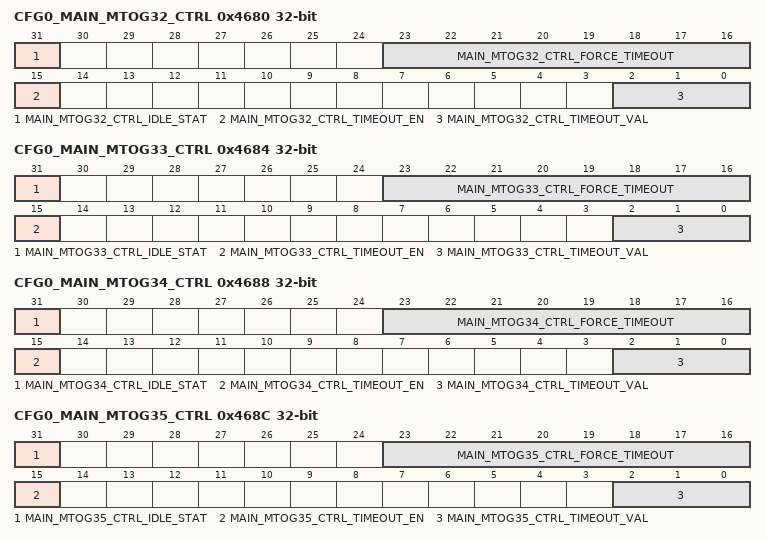
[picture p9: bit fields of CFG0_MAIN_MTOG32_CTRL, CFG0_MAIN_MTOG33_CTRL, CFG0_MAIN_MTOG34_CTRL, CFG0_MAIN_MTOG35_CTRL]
0x4680 CFG0_MAIN_MTOG32_CTRL access per field — Controls timeout operation of Accelerator Cluster ASIL-B master accesses to MSMC (L2) SRAM
  [31] MAIN_MTOG32_CTRL_IDLE_STAT ro — Idle statusWhen high, indicates MTOG32 is idle.
  [23:16] MAIN_MTOG32_CTRL_FORCE_TIMEOUT rw — Force TimeoutForces a flush of the interface transactions. This bitfield is only relevant if timeout_en=1. After forcing a timeout by writing the encoded value, the force_timeout and timeout_en bitfields must be cleared to clear the timeout before re-enabling the gasket. 8'h95 - Force a gasket timeoutAll others - Normal operation
  [15] MAIN_MTOG32_CTRL_TIMEOUT_EN rw — Timeout Enable 1'b0 - Disable the gasket. Clear the interrupt and reset the counter 1'b1 - Enable the timeout gasket functions
  [2:0] MAIN_MTOG32_CTRL_TIMEOUT_VAL rw — Gasket Timeout ValueSelects the number of clock cycles before the interface is considered to have timed out Field values (Others are reserved): 3'b000 - 1024 clock cycles 3'b001 - 4096 clock cycles 3'b010 - 16,384 clock cycles 3'b011 - 65,536 clock cycles 3'b100 - 262,144 clock cycles 3'b101 - 1,048,576 clock cycles 3'b110 - 2,097,152 clock cycles 3'b111 - 4,194,303 clock cycles
0x4684 CFG0_MAIN_MTOG33_CTRL access per field — Controls timeout operation of Accelerator Cluster QueueManager master accesses to MSMC (L2) SRAM
  [31] MAIN_MTOG33_CTRL_IDLE_STAT ro — Idle statusWhen high, indicates MTOG33 is idle.
  [23:16] MAIN_MTOG33_CTRL_FORCE_TIMEOUT rw — Force TimeoutForces a flush of the interface transactions. This bitfield is only relevant if timeout_en=1. After forcing a timeout by writing the encoded value, the force_timeout and timeout_en bitfields must be cleared to clear the timeout before re-enabling the gasket. 8'h95 - Force a gasket timeoutAll others - Normal operation
  [15] MAIN_MTOG33_CTRL_TIMEOUT_EN rw — Timeout Enable 1'b0 - Disable the gasket. Clear the interrupt and reset the counter 1'b1 - Enable the timeout gasket functions
  [2:0] MAIN_MTOG33_CTRL_TIMEOUT_VAL rw — Gasket Timeout ValueSelects the number of clock cycles before the interface is considered to have timed out Field values (Others are reserved): 3'b000 - 1024 clock cycles 3'b001 - 4096 clock cycles 3'b010 - 16,384 clock cycles 3'b011 - 65,536 clock cycles 3'b100 - 262,144 clock cycles 3'b101 - 1,048,576 clock cycles 3'b110 - 2,097,152 clock cycles 3'b111 - 4,194,303 clock cycles
0x4688 CFG0_MAIN_MTOG34_CTRL access per field — Controls timeout operation of Accelerator Cluster ASIL-B master accesses to DDR for OrderIDs 0-4
  [31] MAIN_MTOG34_CTRL_IDLE_STAT ro — Idle statusWhen high, indicates MTOG34 is idle.
  [23:16] MAIN_MTOG34_CTRL_FORCE_TIMEOUT rw — Force TimeoutForces a flush of the interface transactions. This bitfield is only relevant if timeout_en=1. After forcing a timeout by writing the encoded value, the force_timeout and timeout_en bitfields must be cleared to clear the timeout before re-enabling the gasket. 8'h95 - Force a gasket timeoutAll others - Normal operation
  [15] MAIN_MTOG34_CTRL_TIMEOUT_EN rw — Timeout Enable 1'b0 - Disable the gasket. Clear the interrupt and reset the counter 1'b1 - Enable the timeout gasket functions
  [2:0] MAIN_MTOG34_CTRL_TIMEOUT_VAL rw — Gasket Timeout ValueSelects the number of clock cycles before the interface is considered to have timed out Field values (Others are reserved): 3'b000 - 1024 clock cycles 3'b001 - 4096 clock cycles 3'b010 - 16,384 clock cycles 3'b011 - 65,536 clock cycles 3'b100 - 262,144 clock cycles 3'b101 - 1,048,576 clock cycles 3'b110 - 2,097,152 clock cycles 3'b111 - 4,194,303 clock cycles
0x468C CFG0_MAIN_MTOG35_CTRL access per field — Controls timeout operation of Accelerator Cluster QueueManager master accesses to DDR fro OrderIDs 0-4
  [31] MAIN_MTOG35_CTRL_IDLE_STAT ro — Idle statusWhen high, indicates MTOG35 is idle.
  [23:16] MAIN_MTOG35_CTRL_FORCE_TIMEOUT rw — Force TimeoutForces a flush of the interface transactions. This bitfield is only relevant if timeout_en=1. After forcing a timeout by writing the encoded value, the force_timeout and timeout_en bitfields must be cleared to clear the timeout before re-enabling the gasket. 8'h95 - Force a gasket timeoutAll others - Normal operation
  [15] MAIN_MTOG35_CTRL_TIMEOUT_EN rw — Timeout Enable 1'b0 - Disable the gasket. Clear the interrupt and reset the counter 1'b1 - Enable the timeout gasket functions
  [2:0] MAIN_MTOG35_CTRL_TIMEOUT_VAL rw — Gasket Timeout ValueSelects the number of clock cycles before the interface is considered to have timed out Field values (Others are reserved): 3'b000 - 1024 clock cycles 3'b001 - 4096 clock cycles 3'b010 - 16,384 clock cycles 3'b011 - 65,536 clock cycles 3'b100 - 262,144 clock cycles 3'b101 - 1,048,576 clock cycles 3'b110 - 2,097,152 clock cycles 3'b111 - 4,194,303 clock cycles
